# ATA5787 device description
Architecture: AVR8; Family: megaAVR
Registers are 8-bit, access not given, no defined reset value unless marked. A register's access mark holds for its fields unless they carry their own. Offsets are from the block's base; [hi:lo] are bit positions.

## SPI
Instances: SPI 0x00
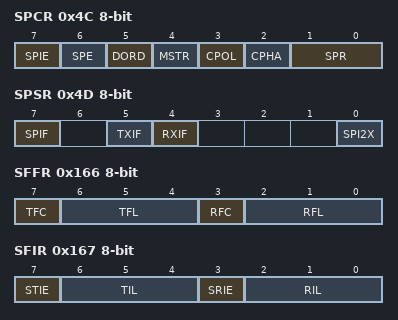
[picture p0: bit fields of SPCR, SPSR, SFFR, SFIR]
0x4C SPCR — SPI Control Register
  [7] SPIE — SPI Interrupt Enable
  [6] SPE — SPI Enable
  [5] DORD — Data Order
  [4] MSTR — Master/Slave Select
  [3] CPOL — Clock Polarity
  [2] CPHA — Clock Phase
  [1:0] SPR — SPI Clock Rate Select
    0=clkio/4; 1=clkio/16; 2=clkio/64; 3=clkio/128; 4=clkio/2; 5=clkio/8; 6=clkio/32; 7=clkio/64
0x4D SPSR — SPI Status Register
  [7] SPIF — SPI Interrupt Flag
  [5] TXIF — Tx Buffer Interrupt Flag
  [4] RXIF — Rx Buffer Interrupt Flag
  [0] SPI2X — Double SPI Speed Bit
0x4E SPDR — SPI Data Register
0x166 SFFR — SPI FIFO Fill Status Register
  [7] TFC — Transmit Buffer Clear
  [6:4] TFL — Transmit Buffer Fill Level
  [3] RFC — Rx Buffer Clear
  [2:0] RFL — Receive Buffer Fill Level
0x167 SFIR — SPI FIFO Interrupt Register
  [7] STIE — SPI Transmit Buffer Interrupt Enable
  [6:4] TIL — Transmit Buffer Interrupt Level
  [3] SRIE — SPI Rx Buffer Interrupt Enable
  [2:0] RIL — Receive Buffer Interrupt Level

## SUP
Instances: SUP 0x00
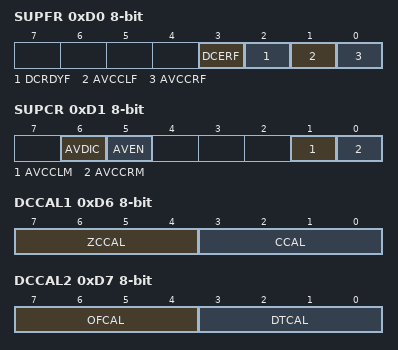
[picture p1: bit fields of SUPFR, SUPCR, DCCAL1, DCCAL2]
0xD0 SUPFR — Supply Flag Register
  [3] DCERF — DCDC Converter Error Flag
  [2] DCRDYF — DCDC Converter Ready Flag
  [1] AVCCLF — AVCC Low Flag
  [0] AVCCRF — AVCC Reset Flag
0xD1 SUPCR — Supply Control Register
  [6] AVDIC — AVCC Double Internal Current
  [5] AVEN — AVCC Enable
  [1] AVCCLM — AVCC Low Interrupt Mask
  [0] AVCCRM — AVCC Reset Interrupt Mask
0xD6 DCCAL1 — DCDC Converter Calibration 1
  [7:4] ZCCAL — Zero Crossing Calibration
  [3:0] CCAL — Current Limit Calibration
0xD7 DCCAL2 — DCDC Converter Calibration 2
  [7:4] OFCAL — Offset Calibration
  [3:0] DTCAL — Dead Time Calibration
0xD8 DCCAL3 — DCDC Converter Calibration 3
  [1:0] SAWCAL — Ramp Calibration
0xD9 DCTST — DCDC Converter Test Mode
  [4:0] DCTST
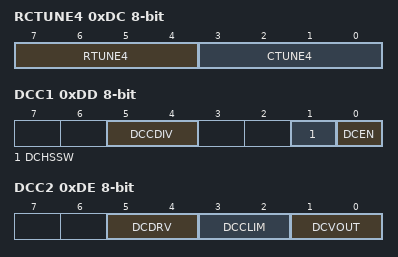
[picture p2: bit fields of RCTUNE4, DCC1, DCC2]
0xDC RCTUNE4 — Resistor Capacitor 4 Bit Tuning
  [7:4] RTUNE4 — 4 Bit Resistor Tuning
  [3:0] CTUNE4 — 4 Bit Capacitor Tuning
0xDD DCC1 — DCDC Converter Control 1
  [5:4] DCCDIV — DCDC Converter Clock Divider
    0=16 (375kHz); 1=12 (500kHz); 2=8 (750kHz); 3=6 (1MHz)
  [1] DCHSSW — DCDC Converter High Side Switch
  [0] DCEN — DCDC Converter Enable
0xDE DCC2 — DCDC Converter Control 2
  [5:4] DCDRV — DCDC Converter Driver Strength
  [3:2] DCCLIM — DCDC Converter Current Limit
  [1:0] DCVOUT — DCDC Converter Output Voltage
    0=2.2V; 1=2.5V; 2=2.8V; 3=3.3V

## TIMER0_WDT
Instances: TIMER0_WDT 0x00
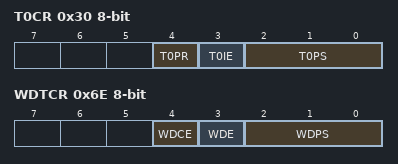
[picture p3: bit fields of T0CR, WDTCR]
0x30 T0CR — Timer0 Control Register
  [4] T0PR — Timer0 Prescaler Reset
  [3] T0IE — Timer0 Interrupt Enable
  [2:0] T0PS — Timer0 Prescaler Select
0x4F T0IFR — Timer0 Interrupt Flag Register
  [0] T0F — Timer0 Flag
0x6E WDTCR — Watchdog Timer0 Control Register
  [4] WDCE — Watchdog Change Enable
  [3] WDE — Watchdog Enable
  [2:0] WDPS — Watchdog Prescaler Select

## TIMER1
Instances: TIMER1 0x00
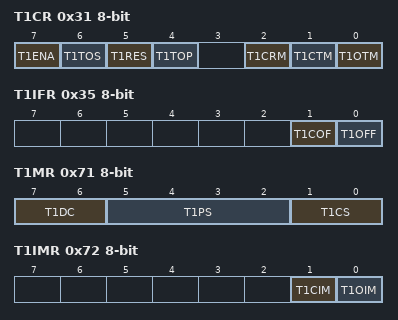
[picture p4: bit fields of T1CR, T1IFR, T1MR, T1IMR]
0x31 T1CR — Timer1 Control Register
  [7] T1ENA — Timer1 Enable
  [6] T1TOS — Timer1 Toggle with Start
  [5] T1RES — Timer1 Reset
  [4] T1TOP — Timer1 Toggle Output Preset
  [2] T1CRM — Timer1 Compare Reset Mask
  [1] T1CTM — Timer1 Compare Toggle Mask
  [0] T1OTM — Timer1 Overflow Toggle Mask
0x35 T1IFR — Timer1 Interrupt Flag Register
  [1] T1COF — Timer1 Compare Flag
  [0] T1OFF — Timer1 Overflow Flag
0x6F T1CNT — Timer1 Counter Register
0x70 T1COR — Timer1 Compare Register
0x71 T1MR — Timer1 Mode Register
  [7:6] T1DC — Timer1 Duty Cycle
  [5:2] T1PS — Timer1 Prescaler Select
  [1:0] T1CS — Timer1 Clock Select
    0=clk_src; 1=clk_frc; 2=clk_T; 3=clk_xto4
0x72 T1IMR — Timer1 Interrupt Mask Register
  [1] T1CIM — Timer1 Compare Interrupt Mask
  [0] T1OIM — Timer1 Overflow Interrupt Mask

## TIMER2
Instances: TIMER2 0x00
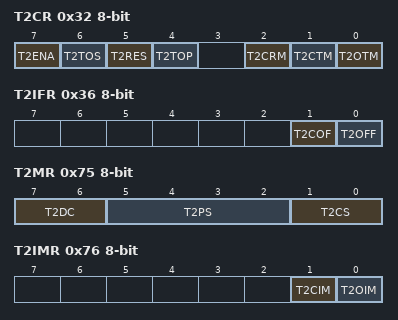
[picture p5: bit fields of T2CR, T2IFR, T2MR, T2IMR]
0x32 T2CR — Timer2 Control Register
  [7] T2ENA — Timer2 Enable
  [6] T2TOS — Timer2 Toggle with Start
  [5] T2RES — Timer2 Reset
  [4] T2TOP — Timer2 Toggle Output Preset
  [2] T2CRM — Timer2 Compare Reset Mask
  [1] T2CTM — Timer2 Compare Toggle Mask
  [0] T2OTM — Timer2 Overflow Toggle Mask
0x36 T2IFR — Timer2 Interrupt Flag Register
  [1] T2COF — Timer2 Compare Flag
  [0] T2OFF — Timer2 Overflow Flag
0x73 T2CNT — Timer2 Counter Register
0x74 T2COR — Timer2 Compare Register
0x75 T2MR — Timer2 Mode Register
  [7:6] T2DC — Timer2 Duty Cycle
  [5:2] T2PS — Timer2 Prescaler Select
  [1:0] T2CS — Timer2 Clock Select
    0=clk_src; 1=clk_vdiv; 2=clk_T; 3=clk_xto4
0x76 T2IMR — Timer2 Interrupt Mask Register
  [1] T2CIM — Timer2 Compare Interrupt Mask
  [0] T2OIM — Timer2 Overflow Interrupt Mask
